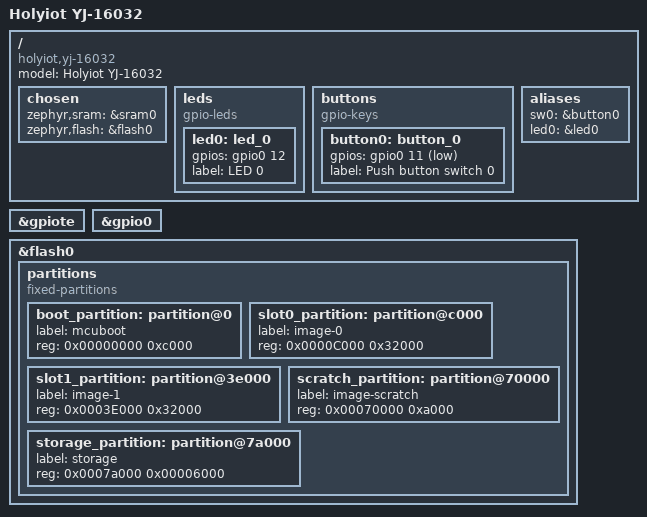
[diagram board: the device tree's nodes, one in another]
/*
 * Copyright (c) 2018 Henrik Brix Andersen <henrik@brixandersen.dk>
 *
 * SPDX-License-Identifier: Apache-2.0
 */

/dts-v1/;
#include <nordic/nrf52832_qfaa.dtsi>

/ {
	model = "Holyiot YJ-16032";
	compatible = "holyiot,yj-16032", "nordic,nrf52832-qfaa",
		     "nordic,nrf52832";

	chosen {
		zephyr,sram = &sram0;
		zephyr,flash = &flash0;
	};

	leds {
		compatible = "gpio-leds";
		led0: led_0 {
			gpios = <&gpio0 12 GPIO_INT_ACTIVE_HIGH>;
			label = "LED 0";
		};
	};

	buttons {
		compatible = "gpio-keys";
		button0: button_0 {
			gpios = <&gpio0 11 GPIO_INT_ACTIVE_LOW>;
			label = "Push button switch 0";
		};
	};

	/* These aliases are provided for compatibility with samples */
	aliases {
		sw0 = &button0;
		led0 = &led0;
	};
};

&gpiote {
	status ="ok";
};

&gpio0 {
	status ="ok";
};

&flash0 {
	/*
	 * For more information, see:
	 * http://docs.zephyrproject.org/latest/devices/dts/flash_partitions.html
	 */
	partitions {
		compatible = "fixed-partitions";
		#address-cells = <1>;
		#size-cells = <1>;

		boot_partition: partition@0 {
			label = "mcuboot";
			reg = <0x00000000 0xc000>;
		};
		slot0_partition: partition@c000 {
			label = "image-0";
			reg = <0x0000C000 0x32000>;
		};
		slot1_partition: partition@3e000 {
			label = "image-1";
			reg = <0x0003E000 0x32000>;
		};
		scratch_partition: partition@70000 {
			label = "image-scratch";
			reg = <0x00070000 0xa000>;
		};
		storage_partition: partition@7a000 {
			label = "storage";
			reg = <0x0007a000 0x00006000>;
		};
	};
};
